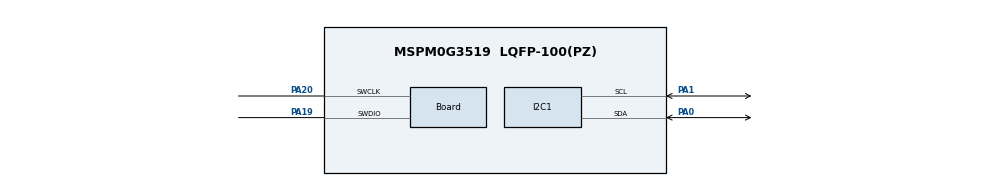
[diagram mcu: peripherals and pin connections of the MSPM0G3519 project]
//@cliArgs --device "MSPM0G351X" --package "LQFP-100(PZ)" --part "Default"
//@v2CliArgs --device "MSPM0G3519" --package "LQFP-100(PZ)"
/**
 * Import the modules used in this configuration.
 */
const Board = scripting.addModule("/ti/driverlib/Board");
const CRCP  = scripting.addModule("/ti/driverlib/CRCP");
const DMA   = scripting.addModule("/ti/driverlib/DMA");
const I2C   = scripting.addModule("/ti/driverlib/I2C", {}, false);
const I2C1  = I2C.addInstance();
// @cliArgs --board /ti/boards/LP_MSPM0G3519 --rtos nortos

/**
 * Write custom configuration values to the imported modules.
 */
Board.peripheral.$assign          = "DEBUGSS";
Board.peripheral.swclkPin.$assign = "PA20";
Board.peripheral.swdioPin.$assign = "PA19";

CRCP.polynomial = "16_POLYNOMIAL_CCIT_ZERO";
CRCP.seed       = 0xFFFF;

I2C1.$name                                 = "I2C_0";
I2C1.basicEnableTarget                     = true;
I2C1.basicTargetAddress                    = 0x48;
I2C1.DMAEvent2                             = "TARGET_RXFIFO_TRIGGER";
I2C1.DMAEvent1                             = "TARGET_TXFIFO_TRIGGER";
I2C1.advTargetTXEmptyEn                    = true;
I2C1.intTarget                             = ["START","STOP","TXFIFO_EMPTY"];
I2C1.peripheral.$assign                    = "I2C0";
I2C1.peripheral.sdaPin.$assign             = "PA0";
I2C1.peripheral.sclPin.$assign             = "PA1";
I2C1.sdaPinConfig.$name                    = "ti_driverlib_gpio_GPIOPinGeneric0";
I2C1.sclPinConfig.$name                    = "ti_driverlib_gpio_GPIOPinGeneric1";
I2C1.DMA_CHANNEL_EVENT2.addressMode        = "f2b";
I2C1.DMA_CHANNEL_EVENT2.dstLength          = "BYTE";
I2C1.DMA_CHANNEL_EVENT2.$name              = "DMA_CH_RX";
I2C1.DMA_CHANNEL_EVENT2.peripheral.$assign = "DMA_CH1";
I2C1.DMA_CHANNEL_EVENT1.srcLength          = "BYTE";
I2C1.DMA_CHANNEL_EVENT1.addressMode        = "b2f";
I2C1.DMA_CHANNEL_EVENT1.$name              = "DMA_CH_TX";
I2C1.DMA_CHANNEL_EVENT1.peripheral.$assign = "DMA_CH0";

const SYSCTL              = scripting.addModule("/ti/driverlib/SYSCTL", {}, false);
SYSCTL.peripheral.$assign = "SYSCTL";

const ProjectConfig              = scripting.addModule("/ti/project_config/ProjectConfig", {}, false);
ProjectConfig.migrationCondition = true;
